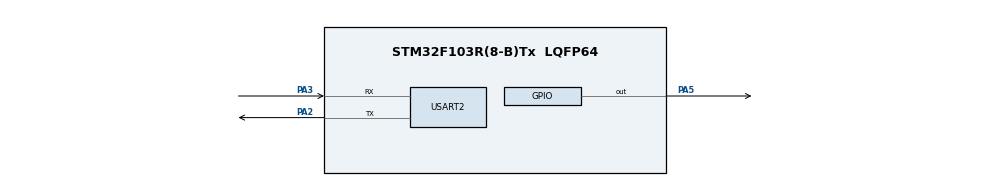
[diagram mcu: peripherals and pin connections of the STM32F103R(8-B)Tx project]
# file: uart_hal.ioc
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Mcu.Family=STM32F1
Mcu.Name=STM32F103R(8-B)Tx
Mcu.Package=LQFP64
NVIC.PriorityGroup=NVIC_PRIORITYGROUP_4
NVIC.USART2_IRQn=true\:0\:0\:false\:true\:true\:1\:true\:true\:true
PA2.Mode=Asynchronous
PA2.Signal=USART2_TX
PA3.Mode=Asynchronous
PA3.Signal=USART2_RX
PA5.Signal=GPIO_Output
PC14-OSC32_IN.Mode=LSE-External-Oscillator
PC14-OSC32_IN.Signal=RCC_OSC32_IN
PC15-OSC32_OUT.Mode=LSE-External-Oscillator
PC15-OSC32_OUT.Signal=RCC_OSC32_OUT
PD0-OSC_IN.Mode=HSE-External-Oscillator
PD0-OSC_IN.Signal=RCC_OSC_IN
PD1-OSC_OUT.Mode=HSE-External-Oscillator
PD1-OSC_OUT.Signal=RCC_OSC_OUT
ProjectManager.HeapSize=0x200
ProjectManager.StackSize=0x400
ProjectManager.TargetToolchain=STM32CubeIDE
RCC.AHBFreq_Value=8000000
RCC.APB1Freq_Value=8000000
RCC.APB1TimFreq_Value=8000000
RCC.APB2Freq_Value=8000000
RCC.APB2TimFreq_Value=8000000
RCC.HCLKFreq_Value=8000000
USART2.VirtualMode=VM_ASYNC
board=custom

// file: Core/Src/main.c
/* USER CODE BEGIN Header */
/**
  ******************************************************************************
  * @file           : main.c
  * @brief          : Main program body
  ******************************************************************************
  * @attention
  *
  * Copyright (c) 2023 STMicroelectronics.
  * All rights reserved.
  *
  * This software is licensed under terms that can be found in the LICENSE file
  * in the root directory of this software component.
  * If no LICENSE file comes with this software, it is provided AS-IS.
  *
  ******************************************************************************
  */
/* USER CODE END Header */
#include "main.h"
#include "usart.h"
#include "gpio.h"

/* USER CODE BEGIN PD */
uint8_t rx2_data[10];
/* USER CODE END PD */

void SystemClock_Config(void);
static void MX_NVIC_Init(void);

int main(void)
{

  /* MCU Configuration--------------------------------------------------------*/

  /* Reset of all peripherals, Initializes the Flash interface and the Systick. */
  HAL_Init();

  /* Configure the system clock */
  SystemClock_Config();

  /* Initialize all configured peripherals */
  MX_GPIO_Init();
  MX_USART2_UART_Init();

  /* Initialize interrupts */
  MX_NVIC_Init();

  /* Infinite loop */
  /* USER CODE BEGIN WHILE */
  uint8_t a = 'a';
  HAL_UART_Receive_IT(&huart2, &rx2_data, 10); // 인터럽트 수신 대기 함수 -> 10개의 문자가 들어와야 실행
  while (1)
  {
    /* USER CODE END WHILE */

    /* USER CODE BEGIN 3 */

	  if(HAL_GPIO_ReadPin(GPIOC, GPIO_PIN_13) == GPIO_PIN_SET){ // LED off condition
		  HAL_GPIO_WritePin(GPIOA, GPIO_PIN_5, GPIO_PIN_RESET); // LED off
//		  HAL_Delay(1000); // delay 는 ms 단위
	  }
	  else { // LED on condition
		  HAL_GPIO_WritePin(GPIOA, GPIO_PIN_5, GPIO_PIN_SET); // LED on
//		  HAL_Delay(1000); // delay 는 ms 단위
		  // UART IP instance pointer, Data pointer, Data size,
//		  HAL_UART_Transmit(&huart2, &a, 1, 10);
	  }
  }
  /* USER CODE END 3 */
}

void SystemClock_Config(void)
{
  RCC_OscInitTypeDef RCC_OscInitStruct = {0};
  RCC_ClkInitTypeDef RCC_ClkInitStruct = {0};

  /** Initializes the RCC Oscillators according to the specified parameters
  * in the RCC_OscInitTypeDef structure.
  */
  RCC_OscInitStruct.OscillatorType = RCC_OSCILLATORTYPE_HSI;
  RCC_OscInitStruct.HSIState = RCC_HSI_ON;
  RCC_OscInitStruct.HSICalibrationValue = RCC_HSICALIBRATION_DEFAULT;
  RCC_OscInitStruct.PLL.PLLState = RCC_PLL_NONE;
  if (HAL_RCC_OscConfig(&RCC_OscInitStruct) != HAL_OK)
  {
    Error_Handler();
  }

  /** Initializes the CPU, AHB and APB buses clocks
  */
  RCC_ClkInitStruct.ClockType = RCC_CLOCKTYPE_HCLK|RCC_CLOCKTYPE_SYSCLK
                              |RCC_CLOCKTYPE_PCLK1|RCC_CLOCKTYPE_PCLK2;
  RCC_ClkInitStruct.SYSCLKSource = RCC_SYSCLKSOURCE_HSI;
  RCC_ClkInitStruct.AHBCLKDivider = RCC_SYSCLK_DIV1;
  RCC_ClkInitStruct.APB1CLKDivider = RCC_HCLK_DIV1;
  RCC_ClkInitStruct.APB2CLKDivider = RCC_HCLK_DIV1;

  if (HAL_RCC_ClockConfig(&RCC_ClkInitStruct, FLASH_LATENCY_0) != HAL_OK)
  {
    Error_Handler();
  }
}

/**
  * @brief NVIC Configuration.
  * @retval None
  */
static void MX_NVIC_Init(void)
{
  /* USART2_IRQn interrupt configuration */
  HAL_NVIC_SetPriority(USART2_IRQn, 0, 0);
  HAL_NVIC_EnableIRQ(USART2_IRQn);
}

/* USER CODE BEGIN 4 */
void HAL_UART_RxCpltCallback(UART_HandleTypeDef *huart)
{
  if(huart->Instance==USART2){
	  HAL_UART_Receive_IT(&huart2, &rx2_data, 10); // receive interrupt 발생 -> 10개 문자가 들어와야 발생
	  HAL_UART_Transmit(&huart2, &rx2_data, 10, 10); // 전송 -> 10개 문자를 송신
//	  HAL_UART_Transmit_IT(&huart2, &rx2_data, 1);
	  HAL_GPIO_WritePin(GPIOA, GPIO_PIN_5, GPIO_PIN_SET); // LED on
//	  HAL_Delay(100); // delay 는 ms 단위
//	  HAL_GPIO_WritePin(GPIOA, GPIO_PIN_5, GPIO_PIN_RESET); // LED off
//	  HAL_UART_Transmit(&huart2, &rx2_data, 1, 10); // 전송
  }
}

/* USER CODE END 4 */

void Error_Handler(void)
{
  __disable_irq();
  while (1)
  {
  }
}
